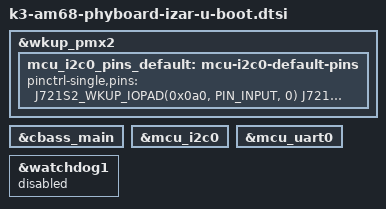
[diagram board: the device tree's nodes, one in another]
// SPDX-License-Identifier: GPL-2.0-only OR MIT
/*
 * Copyright (C) 2025 PHYTEC Messtechnik GmbH
 * Author: Dominik Haller <d.haller@phytec.de>
 *
 * https://www.phytec.eu/en/produkte/development-kits/phyboard-izar/
 */

#include "k3-am68-phycore-som-binman.dtsi"

&wkup_pmx2 {
	mcu_i2c0_pins_default: mcu-i2c0-default-pins {
		pinctrl-single,pins = <
			J721S2_WKUP_IOPAD(0x0a0, PIN_INPUT, 0) /* (G24) MCU_I2C0_SCL */
			J721S2_WKUP_IOPAD(0x0a4, PIN_INPUT, 0) /* (J25) MCU_I2C0_SDA */
		>;
	};
};

&cbass_main {
	bootph-all;
};

&mcu_i2c0 {
	status = "okay";
};

&mcu_uart0 {
	bootph-all;
};

&watchdog1 {
	status = "disabled";
};
